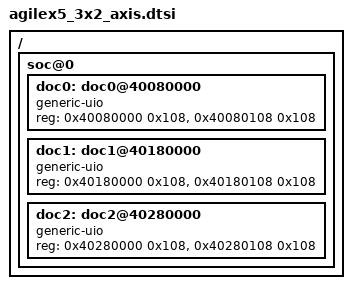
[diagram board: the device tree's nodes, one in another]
/*
* Drive-on-Chip device tree fragment for Agilex 5
*/

/{
	soc@0 {
		doc0: doc0@40080000 {
			compatible = "generic-uio";
			reg = <0x40080000 0x108>,<0x40080108 0x108>;
			reg-names = "axis0","axis1";
		};

		doc1: doc1@40180000 {
			compatible = "generic-uio";
			reg = <0x40180000 0x108>,<0x40180108 0x108>;
			reg-names = "axis0","axis1";
		};

		doc2: doc2@40280000 {
			compatible = "generic-uio";
			reg = <0x40280000 0x108>,<0x40280108 0x108>;
			reg-names = "axis0","axis1";
		};
	};
};
